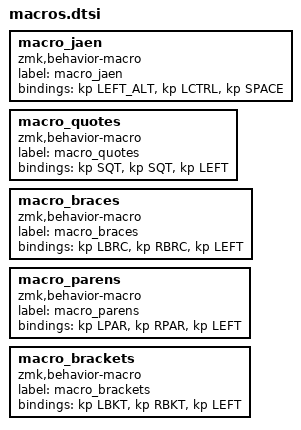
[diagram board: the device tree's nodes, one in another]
macro_jaen: macro_jaen{
compatible = "zmk,behavior-macro";
label = "macro_jaen";
#binding-cells = <0>;
bindings = <&kp LEFT_ALT>, <&kp LCTRL>, <&kp SPACE>;
};
macro_quotes: macro_quotes{
compatible = "zmk,behavior-macro";
label = "macro_quotes";
#binding-cells = <0>;
bindings = <&kp SQT>, <&kp SQT>, <&kp LEFT>;
};
macro_braces: macro_braces{
compatible = "zmk,behavior-macro";
label = "macro_braces";
#binding-cells = <0>;
bindings = <&kp LBRC>, <&kp RBRC>, <&kp LEFT>;
};
macro_parens: macro_parens{
compatible = "zmk,behavior-macro";
label = "macro_parens";
#binding-cells = <0>;
bindings = <&kp LPAR>, <&kp RPAR>, <&kp LEFT>;
};
macro_brackets: macro_brackets{
compatible = "zmk,behavior-macro";
label = "macro_brackets";
#binding-cells = <0>;
bindings = <&kp LBKT>, <&kp RBKT>, <&kp LEFT>;
};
